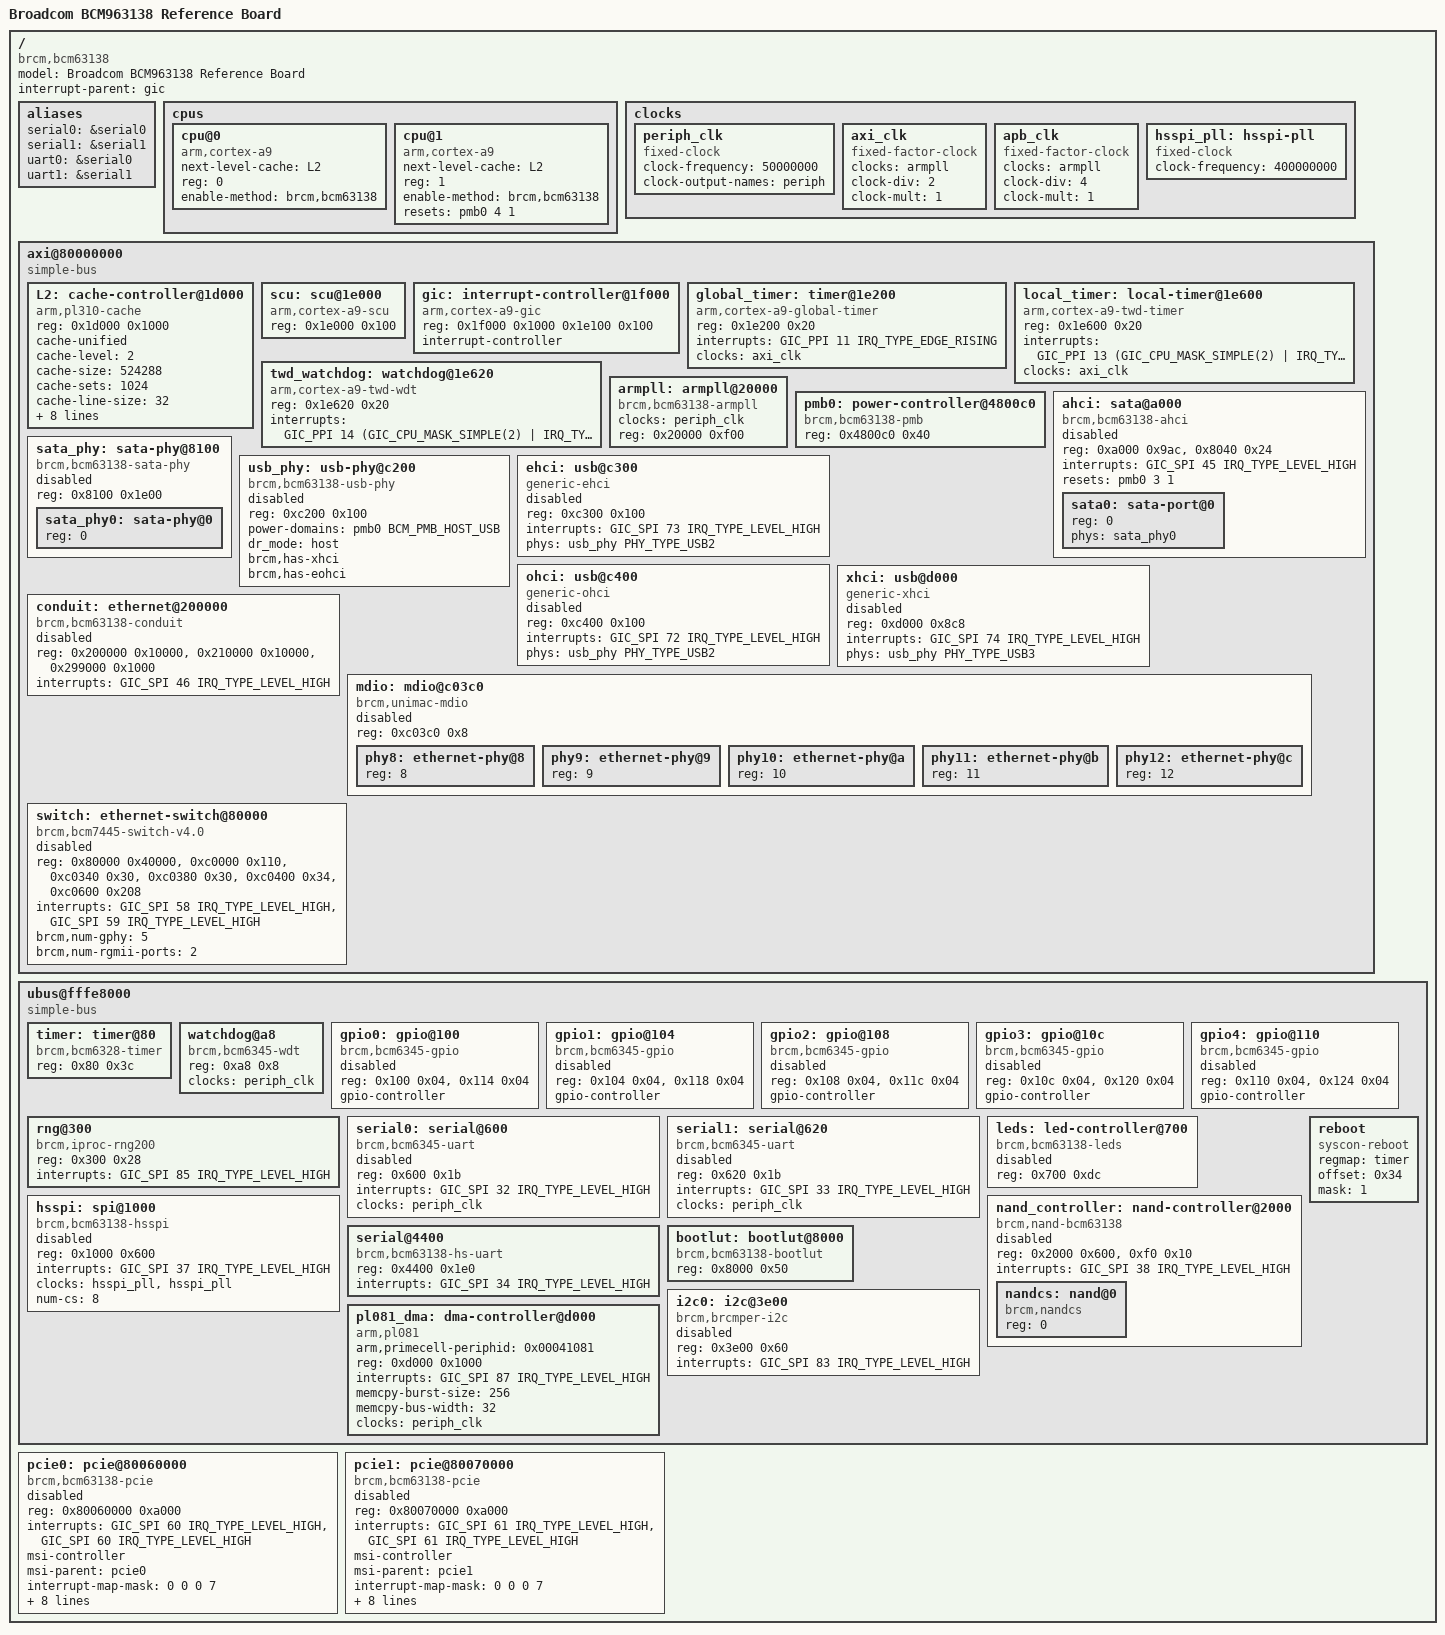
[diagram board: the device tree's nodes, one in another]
// SPDX-License-Identifier: GPL-2.0
/*
 * Broadcom BCM63138 DSL SoCs Device Tree
 */

#include <dt-bindings/interrupt-controller/arm-gic.h>
#include <dt-bindings/interrupt-controller/irq.h>
#include <dt-bindings/phy/phy.h>
#include <dt-bindings/soc/bcm-pmb.h>

/ {
	#address-cells = <1>;
	#size-cells = <1>;
	compatible = "brcm,bcm63138", "brcm,bcmbca";
	model = "Broadcom BCM963138 Reference Board";
	interrupt-parent = <&gic>;

	aliases {
		serial0 = &serial0;
		serial1 = &serial1;
		uart0 = &serial0;
		uart1 = &serial1;
	};

	cpus {
		#address-cells = <1>;
		#size-cells = <0>;

		cpu@0 {
			device_type = "cpu";
			compatible = "arm,cortex-a9";
			next-level-cache = <&L2>;
			reg = <0>;
			enable-method = "brcm,bcm63138";
		};

		cpu@1 {
			device_type = "cpu";
			compatible = "arm,cortex-a9";
			next-level-cache = <&L2>;
			reg = <1>;
			enable-method = "brcm,bcm63138";
			resets = <&pmb0 4 1>;
		};
	};

	clocks {
		/* UBUS peripheral clock */
		periph_clk: periph_clk {
			#clock-cells = <0>;
			compatible = "fixed-clock";
			clock-frequency = <50000000>;
			clock-output-names = "periph";
		};

		/* peripheral clock for system timer */
		axi_clk: axi_clk {
			#clock-cells = <0>;
			compatible = "fixed-factor-clock";
			clocks = <&armpll>;
			clock-div = <2>;
			clock-mult = <1>;
		};

		/* APB bus clock */
		apb_clk: apb_clk {
			#clock-cells = <0>;
			compatible = "fixed-factor-clock";
			clocks = <&armpll>;
			clock-div = <4>;
			clock-mult = <1>;
		};

		hsspi_pll: hsspi-pll {
			compatible = "fixed-clock";
			#clock-cells = <0>;
			clock-frequency = <400000000>;
		};
	};

	/* ARM bus */
	axi@80000000 {
		compatible = "simple-bus";
		ranges = <0 0x80000000 0x784000>;
		#address-cells = <1>;
		#size-cells = <1>;

		L2: cache-controller@1d000 {
			compatible = "arm,pl310-cache";
			reg = <0x1d000 0x1000>;
			cache-unified;
			cache-level = <2>;
			cache-size = <524288>;
			cache-sets = <1024>;
			cache-line-size = <32>;
			prefetch-data = <1>;
			prefetch-instr = <1>;
			arm,double-linefill = <1>;
			arm,double-linefill-incr = <1>;
			arm,double-linefill-wrap = <1>;
			arm,prefetch-drop = <1>;
			arm,prefetch-offset = <7>;
			interrupts = <GIC_PPI 0 IRQ_TYPE_LEVEL_HIGH>;
		};

		scu: scu@1e000 {
			compatible = "arm,cortex-a9-scu";
			reg = <0x1e000 0x100>;
		};

		gic: interrupt-controller@1f000 {
			compatible = "arm,cortex-a9-gic";
			reg = <0x1f000 0x1000
				0x1e100 0x100>;
			#interrupt-cells = <3>;
			#address-cells = <0>;
			interrupt-controller;
		};

		global_timer: timer@1e200 {
			compatible = "arm,cortex-a9-global-timer";
			reg = <0x1e200 0x20>;
			interrupts = <GIC_PPI 11 IRQ_TYPE_EDGE_RISING>;
			clocks = <&axi_clk>;
		};

		local_timer: local-timer@1e600 {
			compatible = "arm,cortex-a9-twd-timer";
			reg = <0x1e600 0x20>;
			interrupts = <GIC_PPI 13 (GIC_CPU_MASK_SIMPLE(2) |
						  IRQ_TYPE_EDGE_RISING)>;
			clocks = <&axi_clk>;
		};

		twd_watchdog: watchdog@1e620 {
			compatible = "arm,cortex-a9-twd-wdt";
			reg = <0x1e620 0x20>;
			interrupts = <GIC_PPI 14 (GIC_CPU_MASK_SIMPLE(2) |
						  IRQ_TYPE_LEVEL_HIGH)>;
		};

		armpll: armpll@20000 {
			#clock-cells = <0>;
			compatible = "brcm,bcm63138-armpll";
			clocks = <&periph_clk>;
			reg = <0x20000 0xf00>;
		};

		pmb0: power-controller@4800c0 {
			compatible = "brcm,bcm63138-pmb";
			reg = <0x4800c0 0x40>;
			#power-domain-cells = <1>;
			#reset-cells = <2>;
		};

		ahci: sata@a000 {
			compatible = "brcm,bcm63138-ahci", "brcm,sata3-ahci";
			reg-names = "ahci", "top-ctrl";
			reg = <0xa000 0x9ac>, <0x8040 0x24>;
			interrupts = <GIC_SPI 45 IRQ_TYPE_LEVEL_HIGH>;
			#address-cells = <1>;
			#size-cells = <0>;
			resets = <&pmb0 3 1>;
			reset-names = "ahci";
			status = "disabled";

			sata0: sata-port@0 {
				reg = <0>;
				phys = <&sata_phy0>;
			};
		};

		sata_phy: sata-phy@8100 {
			compatible = "brcm,bcm63138-sata-phy", "brcm,phy-sata3";
			reg = <0x8100 0x1e00>;
			reg-names = "phy";
			#address-cells = <1>;
			#size-cells = <0>;
			status = "disabled";

			sata_phy0: sata-phy@0 {
				reg = <0>;
				#phy-cells = <0>;
			};
		};

		usb_phy: usb-phy@c200 {
			compatible = "brcm,bcm63138-usb-phy";
			reg = <0xc200 0x100>;
			reg-names = "ctrl";
			power-domains = <&pmb0 BCM_PMB_HOST_USB>;
			dr_mode = "host";
			brcm,has-xhci;
			brcm,has-eohci;
			#phy-cells = <1>;
			status = "disabled";
		};

		ehci: usb@c300 {
			compatible = "generic-ehci";
			reg = <0xc300 0x100>;
			interrupts = <GIC_SPI 73 IRQ_TYPE_LEVEL_HIGH>;
			phys = <&usb_phy PHY_TYPE_USB2>;
			status = "disabled";
		};

		ohci: usb@c400 {
			compatible = "generic-ohci";
			reg = <0xc400 0x100>;
			interrupts = <GIC_SPI 72 IRQ_TYPE_LEVEL_HIGH>;
			phys = <&usb_phy PHY_TYPE_USB2>;
			status = "disabled";
		};

		xhci: usb@d000 {
			compatible = "generic-xhci";
			reg = <0xd000 0x8c8>;
			interrupts = <GIC_SPI 74 IRQ_TYPE_LEVEL_HIGH>;
			phys = <&usb_phy PHY_TYPE_USB3>;
			status = "disabled";
		};

		conduit: ethernet@200000 {
			compatible = "brcm,bcm63138-conduit";
			reg = <0x200000 0x10000>,
			      <0x210000 0x10000>,
			      <0x299000 0x1000>;
			reg-names = "common0", "private0", "regs0";
			interrupts = <GIC_SPI 46 IRQ_TYPE_LEVEL_HIGH>;
			status = "disabled";
		};

		mdio: mdio@c03c0 {
			compatible = "brcm,unimac-mdio";
			reg = <0xc03c0 0x8>;
			reg-names = "mdio";
			#address-cells = <1>;
			#size-cells = <0>;
			status = "disabled";

			phy8: ethernet-phy@8 {
				reg = <8>;
			};

			phy9: ethernet-phy@9 {
				reg = <9>;
			};

			phy10: ethernet-phy@a {
				reg = <10>;
			};

			phy11: ethernet-phy@b {
				reg = <11>;
			};

			phy12: ethernet-phy@c {
				reg = <12>;
			};
		};

		switch: ethernet-switch@80000 {
			compatible = "brcm,bcm7445-switch-v4.0";
			reg = <0x80000 0x40000>,
			      <0xc0000 0x110>,
			      <0xc0340 0x30>,
			      <0xc0380 0x30>,
			      <0xc0400 0x34>,
			      <0xc0600 0x208>;
			reg-names = "core", "reg", "intrl2_0", "intrl2_1", "fcb", "acb";
			interrupts = <GIC_SPI 58 IRQ_TYPE_LEVEL_HIGH>,
				     <GIC_SPI 59 IRQ_TYPE_LEVEL_HIGH>;
			interrupt-names = "switch_0", "switch_1";
			brcm,num-gphy = <5>;
			brcm,num-rgmii-ports = <2>;
			status = "disabled";
		};
	};

	/* Legacy UBUS base */
	ubus@fffe8000 {
		compatible = "simple-bus";
		#address-cells = <1>;
		#size-cells = <1>;
		ranges = <0 0xfffe8000 0x10000>;

		timer: timer@80 {
			compatible = "brcm,bcm6328-timer", "syscon";
			reg = <0x80 0x3c>;
		};

		watchdog@a8 {
			compatible = "brcm,bcm6345-wdt";
			reg = <0xa8 0x8>;
			clocks = <&periph_clk>;
		};

		/* GPIOs 0 .. 31 */
		gpio0: gpio@100 {
			compatible = "brcm,bcm6345-gpio";
			reg = <0x100 0x04>, <0x114 0x04>;
			reg-names = "dirout", "dat";
			gpio-controller;
			#gpio-cells = <2>;
			status = "disabled";
		};

		/* GPIOs 32 .. 63 */
		gpio1: gpio@104 {
			compatible = "brcm,bcm6345-gpio";
			reg = <0x104 0x04>, <0x118 0x04>;
			reg-names = "dirout", "dat";
			gpio-controller;
			#gpio-cells = <2>;
			status = "disabled";
		};

		/* GPIOs 64 .. 95 */
		gpio2: gpio@108 {
			compatible = "brcm,bcm6345-gpio";
			reg = <0x108 0x04>, <0x11c 0x04>;
			reg-names = "dirout", "dat";
			gpio-controller;
			#gpio-cells = <2>;
			status = "disabled";
		};

		/* GPIOs 96 .. 127 */
		gpio3: gpio@10c {
			compatible = "brcm,bcm6345-gpio";
			reg = <0x10c 0x04>, <0x120 0x04>;
			reg-names = "dirout", "dat";
			gpio-controller;
			#gpio-cells = <2>;
			status = "disabled";
		};

		/* GPIOs 128 .. 159 */
		gpio4: gpio@110 {
			compatible = "brcm,bcm6345-gpio";
			reg = <0x110 0x04>, <0x124 0x04>;
			reg-names = "dirout", "dat";
			gpio-controller;
			#gpio-cells = <2>;
			status = "disabled";
		};

		rng@300 {
			compatible = "brcm,iproc-rng200";
			reg = <0x300 0x28>;
			interrupts = <GIC_SPI 85 IRQ_TYPE_LEVEL_HIGH>;
		};

		serial0: serial@600 {
			compatible = "brcm,bcm6345-uart";
			reg = <0x600 0x1b>;
			interrupts = <GIC_SPI 32 IRQ_TYPE_LEVEL_HIGH>;
			clocks = <&periph_clk>;
			clock-names = "periph";
			status = "disabled";
		};

		serial1: serial@620 {
			compatible = "brcm,bcm6345-uart";
			reg = <0x620 0x1b>;
			interrupts = <GIC_SPI 33 IRQ_TYPE_LEVEL_HIGH>;
			clocks = <&periph_clk>;
			clock-names = "periph";
			status = "disabled";
		};

		leds: led-controller@700 {
			#address-cells = <1>;
			#size-cells = <0>;
			compatible = "brcm,bcm63138-leds";
			reg = <0x700 0xdc>;
			status = "disabled";
		};

		hsspi: spi@1000 {
			#address-cells = <1>;
			#size-cells = <0>;
			compatible = "brcm,bcm63138-hsspi", "brcm,bcmbca-hsspi-v1.0";
			reg = <0x1000 0x600>;
			interrupts = <GIC_SPI 37 IRQ_TYPE_LEVEL_HIGH>;
			clocks = <&hsspi_pll &hsspi_pll>;
			clock-names = "hsspi", "pll";
			num-cs = <8>;
			status = "disabled";
		};

		nand_controller: nand-controller@2000 {
			#address-cells = <1>;
			#size-cells = <0>;
			compatible = "brcm,nand-bcm63138", "brcm,brcmnand-v7.0", "brcm,brcmnand";
			reg = <0x2000 0x600>, <0xf0 0x10>;
			reg-names = "nand", "nand-int-base";
			status = "disabled";
			interrupts = <GIC_SPI 38 IRQ_TYPE_LEVEL_HIGH>;
			interrupt-names = "nand_ctlrdy";

			nandcs: nand@0 {
				compatible = "brcm,nandcs";
				reg = <0>;
			};
		};

		serial@4400 {
			compatible = "brcm,bcm63138-hs-uart", "brcm,bcmbca-hs-uart";
			reg = <0x4400 0x1e0>;
			interrupts = <GIC_SPI 34 IRQ_TYPE_LEVEL_HIGH>;
		};

		bootlut: bootlut@8000 {
			compatible = "brcm,bcm63138-bootlut";
			reg = <0x8000 0x50>;
		};

		i2c0: i2c@3e00 {
			compatible = "brcm,brcmper-i2c";
			reg = <0x3e00 0x60>;
			interrupts = <GIC_SPI 83 IRQ_TYPE_LEVEL_HIGH>;
			#address-cells = <1>;
			#size-cells = <0>;
			status = "disabled";
		};

		pl081_dma: dma-controller@d000 {
			compatible = "arm,pl081", "arm,primecell";
			// The magic B105F00D info is missing
			arm,primecell-periphid = <0x00041081>;
			reg = <0xd000 0x1000>;
			interrupts = <GIC_SPI 87 IRQ_TYPE_LEVEL_HIGH>;
			memcpy-burst-size = <256>;
			memcpy-bus-width = <32>;
			clocks = <&periph_clk>;
			clock-names = "apb_pclk";
			#dma-cells = <2>;
		};

		reboot {
			compatible = "syscon-reboot";
			regmap = <&timer>;
			offset = <0x34>;
			mask = <1>;
		};
	};

	pcie0: pcie@80060000 {
		compatible = "brcm,bcm63138-pcie", "brcm,bcm7445-pcie";
		reg = <0x80060000 0xa000>;
		device_type = "pci";
		#address-cells = <3>;
		#size-cells = <2>;
		#interrupt-cells = <1>;
		interrupts = <GIC_SPI 60 IRQ_TYPE_LEVEL_HIGH>,
			     <GIC_SPI 60 IRQ_TYPE_LEVEL_HIGH>;
		interrupt-names = "pcie", "msi";
		msi-controller;
		msi-parent = <&pcie0>;
		interrupt-map-mask = <0 0 0 7>;
		interrupt-map = <0 0 0 1 &gic GIC_SPI 60 IRQ_TYPE_LEVEL_HIGH>,
				<0 0 0 2 &gic GIC_SPI 60 IRQ_TYPE_LEVEL_HIGH>,
				<0 0 0 3 &gic GIC_SPI 60 IRQ_TYPE_LEVEL_HIGH>,
				<0 0 0 4 &gic GIC_SPI 60 IRQ_TYPE_LEVEL_HIGH>;
		ranges = <0x02000000 0 0x90000000 0x90000000 0 0x10000000>;
		dma-ranges = <0x02000000 0 0x00000000 0x00000000 0 0x40000000>;
		power-domains = <&pmb0 BCM_PMB_PCIE0>;
		status = "disabled";
	};

	pcie1: pcie@80070000 {
		compatible = "brcm,bcm63138-pcie", "brcm,bcm7445-pcie";
		reg = <0x80070000 0xa000>;
		device_type = "pci";
		#address-cells = <3>;
		#size-cells = <2>;
		#interrupt-cells = <1>;
		interrupts = <GIC_SPI 61 IRQ_TYPE_LEVEL_HIGH>,
			     <GIC_SPI 61 IRQ_TYPE_LEVEL_HIGH>;
		interrupt-names = "pcie", "msi";
		msi-controller;
		msi-parent = <&pcie1>;
		interrupt-map-mask = <0 0 0 7>;
		interrupt-map = <0 0 0 1 &gic GIC_SPI 61 IRQ_TYPE_LEVEL_HIGH>,
				<0 0 0 2 &gic GIC_SPI 61 IRQ_TYPE_LEVEL_HIGH>,
				<0 0 0 3 &gic GIC_SPI 61 IRQ_TYPE_LEVEL_HIGH>,
				<0 0 0 4 &gic GIC_SPI 61 IRQ_TYPE_LEVEL_HIGH>;
		ranges = <0x02000000 0 0xa0000000 0xa0000000 0 0x10000000>;
		dma-ranges = <0x02000000 0 0x00000000 0x00000000 0 0x40000000>;
		power-domains = <&pmb0 BCM_PMB_PCIE1>;
		status = "disabled";
	};
};
